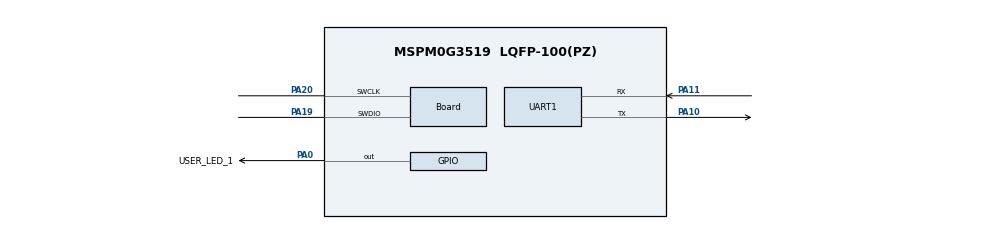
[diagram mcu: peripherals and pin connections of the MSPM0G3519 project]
//@cliArgs --device "MSPM0G351X" --package "LQFP-100(PZ)" --part "Default"
//@v2CliArgs --device "MSPM0G3519" --package "LQFP-100(PZ)"
// @cliArgs --board /ti/boards/LP_MSPM0G3519 --rtos nortos

/**
 * Import the modules used in this configuration.
 */
const Board  = scripting.addModule("/ti/driverlib/Board");
const GPIO   = scripting.addModule("/ti/driverlib/GPIO", {}, false);
const GPIO1  = GPIO.addInstance();
const SYSCTL = scripting.addModule("/ti/driverlib/SYSCTL");
const UART   = scripting.addModule("/ti/driverlib/UART", {}, false);
const UART1  = UART.addInstance();

/**
 * Write custom configuration values to the imported modules.
 */
Board.peripheral.$assign          = "DEBUGSS";
Board.peripheral.swclkPin.$assign = "PA20";
Board.peripheral.swdioPin.$assign = "PA19";

GPIO1.$name                                 = "GPIO_LEDS";
GPIO1.associatedPins[0].$name               = "USER_LED_1";
GPIO1.associatedPins[0].assignedPort        = "PORTA";
GPIO1.associatedPins[0].assignedPortSegment = "Lower";
GPIO1.associatedPins[0].pin.$assign         = "PA0";

SYSCTL.forceDefaultClkConfig = true;
SYSCTL.clockTreeEn           = true;

UART1.$name                    = "UART_0";
UART1.enableFIFO               = true;
UART1.enableExtend             = true;
UART1.enableIrda               = true;
UART1.setIrdaPulseLength       = 5;
UART1.uartClkDiv2              = "3";
UART1.uartClkDiv               = "3";
UART1.enableMSBFirst           = true;
UART1.peripheral.$assign       = "UART0";
UART1.peripheral.rxPin.$assign = "PA11";
UART1.peripheral.txPin.$assign = "PA10";
UART1.txPinConfig.enableConfig = true;
UART1.txPinConfig.invert       = "ENABLE";
UART1.rxPinConfig.enableConfig = true;
UART1.rxPinConfig.invert       = "ENABLE";

const ProjectConfig              = scripting.addModule("/ti/project_config/ProjectConfig", {}, false);
ProjectConfig.migrationCondition = true;
